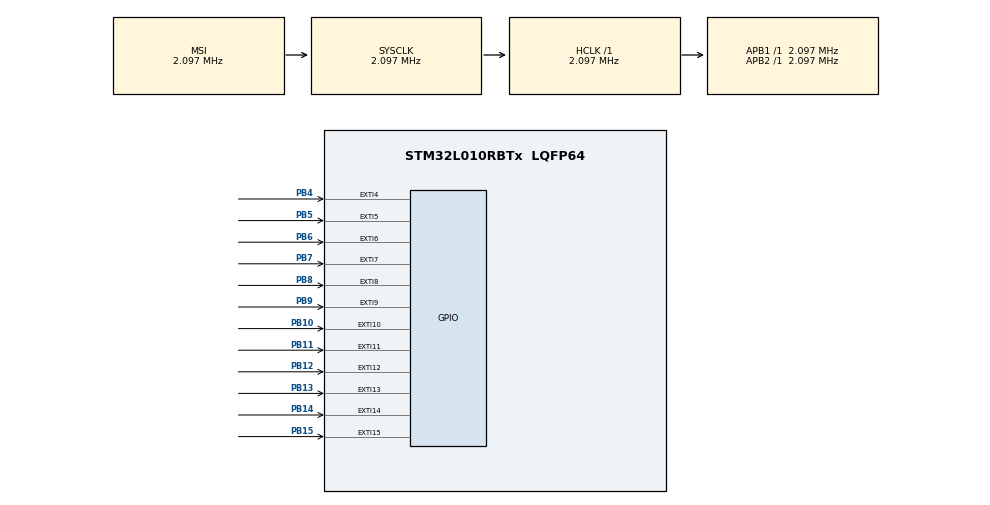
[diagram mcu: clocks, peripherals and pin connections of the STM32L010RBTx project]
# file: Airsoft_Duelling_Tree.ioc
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FREERTOS.Tasks01=defaultTask,0,128,StartDefaultTask,Default,NULL,Dynamic,NULL,NULL
Mcu.Family=STM32L0
Mcu.Name=STM32L010RBTx
Mcu.Package=LQFP64
NVIC.EXTI4_15_IRQn=true\:0\:0\:false\:false\:true\:false\:true\:true
NVIC.TIM2_IRQn=true\:0\:0\:false\:false\:true\:false\:false\:true
NVIC.TimeBase=TIM2_IRQn
NVIC.TimeBaseIP=TIM2
PB10.GPIO_PuPd=GPIO_PULLDOWN
PB10.Signal=GPXTI10
PB11.GPIO_PuPd=GPIO_PULLDOWN
PB11.Signal=GPXTI11
PB12.GPIO_PuPd=GPIO_PULLDOWN
PB12.Signal=GPXTI12
PB13.GPIO_PuPd=GPIO_PULLDOWN
PB13.Signal=GPXTI13
PB14.GPIO_PuPd=GPIO_PULLDOWN
PB14.Signal=GPXTI14
PB15.GPIO_PuPd=GPIO_PULLDOWN
PB15.Signal=GPXTI15
PB4.GPIO_PuPd=GPIO_PULLDOWN
PB4.Signal=GPXTI4
PB5.GPIO_PuPd=GPIO_PULLDOWN
PB5.Signal=GPXTI5
PB6.GPIO_PuPd=GPIO_PULLDOWN
PB6.Signal=GPXTI6
PB7.GPIO_PuPd=GPIO_PULLDOWN
PB7.Signal=GPXTI7
PB8.GPIO_PuPd=GPIO_PULLDOWN
PB8.Signal=GPXTI8
PB9.GPIO_PuPd=GPIO_PULLDOWN
PB9.Signal=GPXTI9
ProjectManager.HeapSize=0x200
ProjectManager.StackSize=0x400
ProjectManager.TargetToolchain=STM32CubeIDE
RCC.AHBFreq_Value=2097000
RCC.APB1Freq_Value=2097000
RCC.APB1TimFreq_Value=2097000
RCC.APB2Freq_Value=2097000
RCC.APB2TimFreq_Value=2097000
RCC.HSE_VALUE=8000000
RCC.HSI16_VALUE=16000000
RCC.HSI_VALUE=16000000
RCC.LSE_VALUE=32768
RCC.MSI_VALUE=2097000
RCC.SYSCLKFreq_VALUE=2097000
RCC.VCOOutputFreq_Value=48000000
VP_FREERTOS_VS_CMSIS_V1.Mode=CMSIS_V1
VP_SYS_VS_tim2.Mode=TIM2
board=custom

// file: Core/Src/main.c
/* USER CODE BEGIN Header */
/**
  ******************************************************************************
  * @file           : main.c
  * @brief          : Main program body
  ******************************************************************************
  * @attention
  *
  * <h2><center>&copy; Copyright (c) 2020 STMicroelectronics.
  * All rights reserved.</center></h2>
  *
  * This software component is licensed by ST under BSD 3-Clause license,
  * the "License"; You may not use this file except in compliance with the
  * License. You may obtain a copy of the License at:
  *                        opensource.org/licenses/BSD-3-Clause
  *
  ******************************************************************************
  */
/* USER CODE END Header */
#include "main.h"
#include "cmsis_os.h"

/* USER CODE BEGIN Includes */
//#include "statemachine.h"

/* USER CODE END Includes */

osThreadId defaultTaskHandle;

void SystemClock_Config(void);
static void MX_GPIO_Init(void);
void StartDefaultTask(void const * argument);

int main(void)
{

  /* MCU Configuration--------------------------------------------------------*/

  /* Reset of all peripherals, Initializes the Flash interface and the Systick. */
  HAL_Init();

  /* Configure the system clock */
  SystemClock_Config();

  /* Initialize all configured peripherals */
  MX_GPIO_Init();

  /* Create the thread(s) */
  /* definition and creation of defaultTask */
  osThreadDef(defaultTask, StartDefaultTask, osPriorityNormal, 0, 128);
  defaultTaskHandle = osThreadCreate(osThread(defaultTask), NULL);

  /* Start scheduler */
  osKernelStart();

  /* We should never get here as control is now taken by the scheduler */
  /* Infinite loop */
  while (1)
  {

  }
}

void SystemClock_Config(void)
{
  RCC_OscInitTypeDef RCC_OscInitStruct = {0};
  RCC_ClkInitTypeDef RCC_ClkInitStruct = {0};

  /** Configure the main internal regulator output voltage
  */
  __HAL_PWR_VOLTAGESCALING_CONFIG(PWR_REGULATOR_VOLTAGE_SCALE1);
  /** Initializes the RCC Oscillators according to the specified parameters
  * in the RCC_OscInitTypeDef structure.
  */
  RCC_OscInitStruct.OscillatorType = RCC_OSCILLATORTYPE_MSI;
  RCC_OscInitStruct.MSIState = RCC_MSI_ON;
  RCC_OscInitStruct.MSICalibrationValue = 0;
  RCC_OscInitStruct.MSIClockRange = RCC_MSIRANGE_5;
  RCC_OscInitStruct.PLL.PLLState = RCC_PLL_NONE;
  if (HAL_RCC_OscConfig(&RCC_OscInitStruct) != HAL_OK)
  {
    Error_Handler();
  }
  /** Initializes the CPU, AHB and APB buses clocks
  */
  RCC_ClkInitStruct.ClockType = RCC_CLOCKTYPE_HCLK|RCC_CLOCKTYPE_SYSCLK
                              |RCC_CLOCKTYPE_PCLK1|RCC_CLOCKTYPE_PCLK2;
  RCC_ClkInitStruct.SYSCLKSource = RCC_SYSCLKSOURCE_MSI;
  RCC_ClkInitStruct.AHBCLKDivider = RCC_SYSCLK_DIV1;
  RCC_ClkInitStruct.APB1CLKDivider = RCC_HCLK_DIV1;
  RCC_ClkInitStruct.APB2CLKDivider = RCC_HCLK_DIV1;

  if (HAL_RCC_ClockConfig(&RCC_ClkInitStruct, FLASH_LATENCY_0) != HAL_OK)
  {
    Error_Handler();
  }
}

static void MX_GPIO_Init(void)
{
  GPIO_InitTypeDef GPIO_InitStruct = {0};

  /* GPIO Ports Clock Enable */
  __HAL_RCC_GPIOB_CLK_ENABLE();

  /*Configure GPIO pins : PB10 PB11 PB12 PB13
                           PB14 PB15 PB4 PB5
                           PB6 PB7 PB8 PB9 */
  GPIO_InitStruct.Pin = GPIO_PIN_10|GPIO_PIN_11|GPIO_PIN_12|GPIO_PIN_13
                          |GPIO_PIN_14|GPIO_PIN_15|GPIO_PIN_4|GPIO_PIN_5
                          |GPIO_PIN_6|GPIO_PIN_7|GPIO_PIN_8|GPIO_PIN_9;
  GPIO_InitStruct.Mode = GPIO_MODE_IT_RISING;
  GPIO_InitStruct.Pull = GPIO_PULLDOWN;
  HAL_GPIO_Init(GPIOB, &GPIO_InitStruct);

  /* EXTI interrupt init*/
  HAL_NVIC_SetPriority(EXTI4_15_IRQn, 0, 0);
  HAL_NVIC_EnableIRQ(EXTI4_15_IRQn);

}

void StartDefaultTask(void const * argument)
{
  /* USER CODE BEGIN 5 */
  /* Infinite loop */
  for(;;)
  {
//	main_statemachine();
    osDelay(1);
  }
  /* USER CODE END 5 */
}

void HAL_TIM_PeriodElapsedCallback(TIM_HandleTypeDef *htim)
{
  if (htim->Instance == TIM2) {
    HAL_IncTick();
  }
}

void Error_Handler(void)
{
}

/************************ (C) COPYRIGHT STMicroelectronics *****END OF FILE****/
